# DSS0_OVR1 register map
Vendor: Texas Instruments
Peripheral module from a debugger description file (folder J7ES).
Registers are 32-bit, read-write, reset 0x0 unless marked. A register's access mark holds for its fields unless they carry their own. Offsets are as the file gives them; lines under a group give offsets from that group; [hi:lo] are bit positions; {n}, {i} and the like mark numbered series; 'fields as' and 'values as' point back to an identical list; <NAME> marks a mode.

## DSS0_OVR1
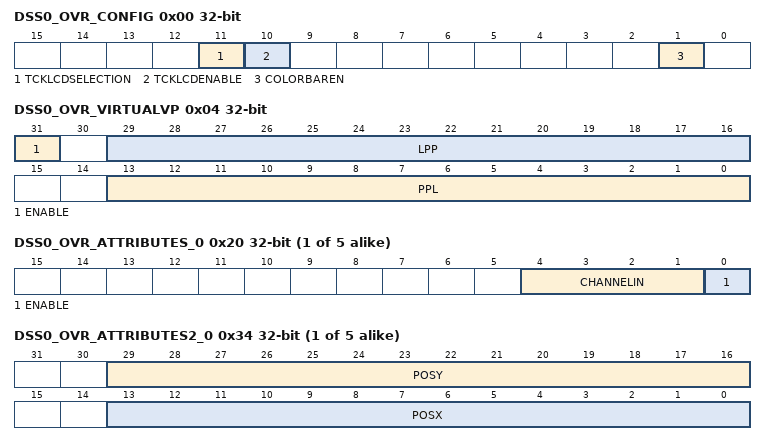
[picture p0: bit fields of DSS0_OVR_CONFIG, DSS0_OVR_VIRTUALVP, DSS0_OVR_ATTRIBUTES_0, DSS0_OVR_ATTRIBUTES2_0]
0x00 DSS0_OVR_CONFIG access per field — The control register configures the Display Controller module for the VP output. Shadow register
  [11] TCKLCDSELECTION rw — Transparency Color Key Selection
  [10] TCKLCDENABLE rw — Transparency Color Key Enable
  [1] COLORBAREN rw — Enable the Color-Bar
0x04 DSS0_OVR_VIRTUALVP — Configures the new VIRTUAL VP operation. Shadow register
  [31] ENABLE — Enable the Virtual VP Operation
  [29:16] LPP — Lines per panel Encoded value [from 1 to 16384] to specify the number of lines on the Virtual VP [program to value minus 1]
  [13:0] PPL — Pixels per line Encoded value [from 1 to 16384] to specify the number of pixels contains within each line on the Virtual VP [program to value minus 1]
0x08 DSS0_OVR_DEFAULT_COLOR — The control register configures the default solid background color LSB[31:0]. Shadow register
  [31:0] DEFAULTCOLOR — 32-bit LSB of ARGB background color
0x0C DSS0_OVR_DEFAULT_COLOR2 access per field — The control register configures the default solid background color MSB[47:32]. Shadow register
  [15:0] DEFAULTCOLOR rw
0x10 DSS0_OVR_TRANS_COLOR_MAX — The register sets the max transparency color value for the overlays. Shadow register
  [31:0] TRANSCOLORKEY — LSB[31:0].
0x14 DSS0_OVR_TRANS_COLOR_MAX2 access per field — The register sets the max transparency color value for the overlays. Shadow register
  [3:0] TRANSCOLORKEY rw — MSB
0x18 DSS0_OVR_TRANS_COLOR_MIN — The register sets the min transparency color value for the overlays. Shadow register
  [31:0] TRANSCOLORKEY — LSB[31:0].
0x1C DSS0_OVR_TRANS_COLOR_MIN2 access per field — The register sets the min transparency color value for the overlays. Shadow register
  [3:0] TRANSCOLORKEY rw — MSB
{0x20+4i} DSS0_OVR_ATTRIBUTES_{i} (i=0..4) — The register configures the attributes of layer-{i}, ZORDER= {i}, of the Overlay manager. Shadow register
  [4:1] CHANNELIN — Input channel connected to Layer
  [0] ENABLE — Layer Enable
{0x34+4i} DSS0_OVR_ATTRIBUTES2_{i} (i=0..4) — The register configures the additional attributes of layer-{i}, ZORDER= {i}, of the Overlay manager. Shadow register
  [29:16] POSY — Y position of the layer.
  [13:0] POSX — X position of the layer.
0x48 DSS0_OVR_SECURE access per field — Security bit settings for the sub-module
  [0] SECURE rw
